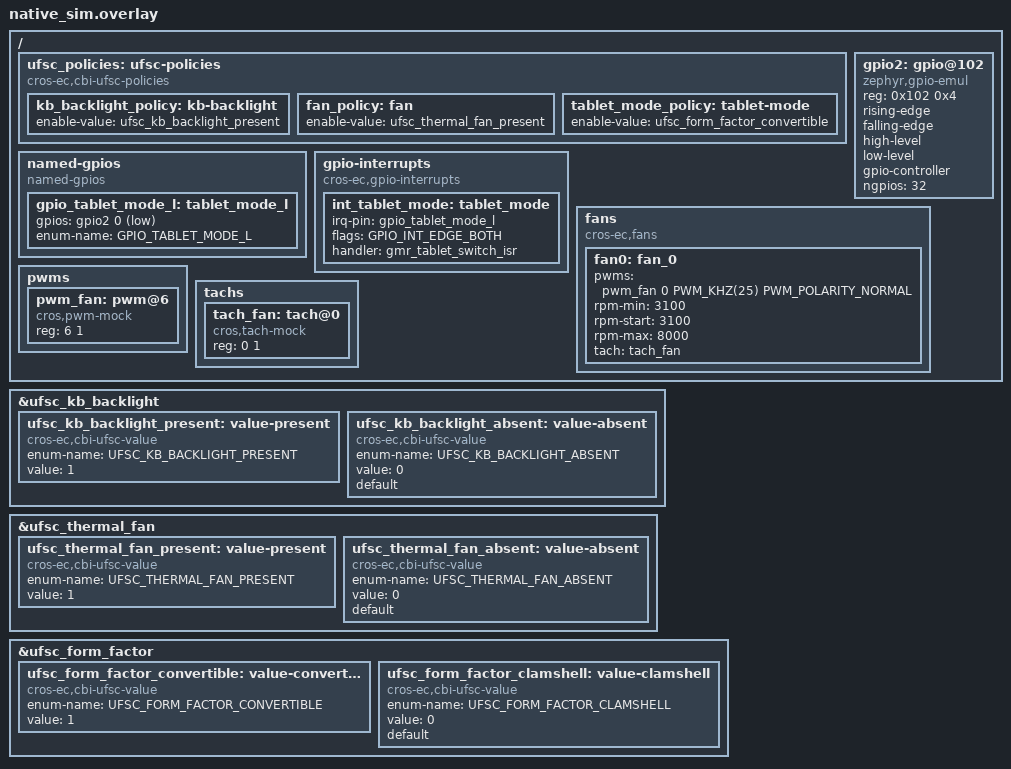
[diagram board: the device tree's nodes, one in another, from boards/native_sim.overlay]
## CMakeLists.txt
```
# Copyright 2026 The ChromiumOS Authors
# Use of this source code is governed by a BSD-style license that can be
# found in the LICENSE file.

zephyr_include_directories(include)

target_sources(app PRIVATE
	src/mock_cbi.c
	src/ufsc_kb_backlight.c
	src/ufsc_thermal_fan.c
	src/ufsc_tablet_mode.c
)
```

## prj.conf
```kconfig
# Copyright 2026 The ChromiumOS Authors
# Use of this source code is governed by a BSD-style license that can be
# found in the LICENSE file.

CONFIG_PLATFORM_EC_CBI_FLASH=y
CONFIG_PLATFORM_EC_PWM_KBLIGHT=y
CONFIG_PLATFORM_EC_FLASH_SIZE_BYTES=0x80000
CONFIG_PLATFORM_EC_GMR_TABLET_MODE=y
CONFIG_PLATFORM_EC_TABLET_MODE=y
CONFIG_PLATFORM_EC_TABLET_MODE_SWITCH=y
```

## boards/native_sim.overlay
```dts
/* Copyright 2026 The ChromiumOS Authors
 * Use of this source code is governed by a BSD-style license that can be
 * found in the LICENSE file.
 */

#include <cros/cbi_ufsc_std_schema.dtsi>

/ {
	ufsc_policies: ufsc-policies {
		compatible = "cros-ec,cbi-ufsc-policies";

		kb_backlight_policy: kb-backlight {
			enable-value = <&ufsc_kb_backlight_present>;
		};

		fan_policy: fan {
			enable-value = <&ufsc_thermal_fan_present>;
		};

		tablet_mode_policy: tablet-mode {
			enable-value = <&ufsc_form_factor_convertible>;
		};
	};

	gpio2: gpio@102 {
		status = "okay";
		compatible = "zephyr,gpio-emul";
		reg = <0x102 0x4>;
		rising-edge;
		falling-edge;
		high-level;
		low-level;
		gpio-controller;
		#gpio-cells = <2>;
		ngpios = <32>;
	};

	named-gpios {
		compatible = "named-gpios";

		gpio_tablet_mode_l: tablet_mode_l {
			gpios = <&gpio2 0 (GPIO_INPUT | GPIO_ACTIVE_LOW)>;
			enum-name = "GPIO_TABLET_MODE_L";
		};
	};

	gpio-interrupts {
		compatible = "cros-ec,gpio-interrupts";

		int_tablet_mode: tablet_mode {
			irq-pin = <&gpio_tablet_mode_l>;
			flags = <GPIO_INT_EDGE_BOTH>;
			handler = "gmr_tablet_switch_isr";
		};
	};

	fans {
		compatible = "cros-ec,fans";

		fan0: fan_0 {
			pwms = <&pwm_fan 0 PWM_KHZ(25) PWM_POLARITY_NORMAL>;
			rpm-min = <3100>;
			rpm-start = <3100>;
			rpm-max = <8000>;
			tach = <&tach_fan>;
		};
	};

	pwms {
		pwm_fan: pwm@6 {
			compatible = "cros,pwm-mock";
			reg = <6 1>;
			#pwm-cells = <3>;
			status = "okay";
		};
	};

	tachs {
		#address-cells = <1>;
		#size-cells = <1>;

		tach_fan: tach@0 {
			compatible = "cros,tach-mock";
			reg = <0 1>;
			#tach-cells = <3>;
			status = "okay";
		};
	};
};

&ufsc_kb_backlight {
	status = "okay";
	ufsc_kb_backlight_present: value-present {
		compatible = "cros-ec,cbi-ufsc-value";
		status = "okay";
		enum-name = "UFSC_KB_BACKLIGHT_PRESENT";
		value = <1>;
	};
	ufsc_kb_backlight_absent: value-absent {
		compatible = "cros-ec,cbi-ufsc-value";
		status = "okay";
		enum-name = "UFSC_KB_BACKLIGHT_ABSENT";
		value = <0>;
		default;
	};
};

&ufsc_thermal_fan {
	status = "okay";
	ufsc_thermal_fan_present: value-present {
		compatible = "cros-ec,cbi-ufsc-value";
		status = "okay";
		enum-name = "UFSC_THERMAL_FAN_PRESENT";
		value = <1>;
	};
	ufsc_thermal_fan_absent: value-absent {
		compatible = "cros-ec,cbi-ufsc-value";
		status = "okay";
		enum-name = "UFSC_THERMAL_FAN_ABSENT";
		value = <0>;
		default;
	};
};

&ufsc_form_factor {
	status = "okay";
	ufsc_form_factor_convertible: value-convertible {
		compatible = "cros-ec,cbi-ufsc-value";
		status = "okay";
		enum-name = "UFSC_FORM_FACTOR_CONVERTIBLE";
		value = <1>;
	};
	ufsc_form_factor_clamshell: value-clamshell {
		compatible = "cros-ec,cbi-ufsc-value";
		status = "okay";
		enum-name = "UFSC_FORM_FACTOR_CLAMSHELL";
		value = <0>;
		default;
	};
};
```

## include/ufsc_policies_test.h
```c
/* Copyright 2026 The ChromiumOS Authors
 * Use of this source code is governed by a BSD-style license that can be
 * found in the LICENSE file.
 */

#ifndef PLATFORM_EC_ZEPHYR_TEST_DRIVERS_UFSC_POLICIES_INCLUDE_UFSC_POLICIES_TEST_H_
#define PLATFORM_EC_ZEPHYR_TEST_DRIVERS_UFSC_POLICIES_INCLUDE_UFSC_POLICIES_TEST_H_

#include "cros_cbi.h"

#include <zephyr/fff.h>

DECLARE_FAKE_VALUE_FUNC(bool, cros_cbi_ufsc_check_match,
			enum cbi_ufsc_value_id);

#endif /* PLATFORM_EC_ZEPHYR_TEST_DRIVERS_UFSC_POLICIES_INCLUDE_UFSC_POLICIES_TEST_H_ \
	*/
```

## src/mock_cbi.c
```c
/* Copyright 2026 The ChromiumOS Authors
 * Use of this source code is governed by a BSD-style license that can be
 * found in the LICENSE file.
 */

#include "ufsc_policies_test.h"

DEFINE_FAKE_VALUE_FUNC(bool, cros_cbi_ufsc_check_match, enum cbi_ufsc_value_id);
```

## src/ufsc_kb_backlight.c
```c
/* Copyright 2026 The ChromiumOS Authors
 * Use of this source code is governed by a BSD-style license that can be
 * found in the LICENSE file.
 */

#include "cros_cbi.h"
#include "ec_commands.h"
#include "hooks.h"
#include "host_command.h"
#include "keyboard_backlight.h"
#include "system.h"
#include "ufsc_policies_test.h"

#include <zephyr/fff.h>
#include <zephyr/ztest.h>

#define VALUE_NODE_PRESENT DT_NODELABEL(ufsc_kb_backlight_present)

static bool mock_ufsc_kb_backlight_present;

static bool mock_cbi_ufsc_check_match(enum cbi_ufsc_value_id value_id)
{
	if (value_id == CBI_UFSC_VALUE_ID(VALUE_NODE_PRESENT)) {
		return mock_ufsc_kb_backlight_present;
	}
	/* Default to false for any other UFSC checks in the system */
	return false;
}

static void ufsc_kb_backlight_before(void *data)
{
	ARG_UNUSED(data);

	/* Replace the real function with our custom fake. */
	cros_cbi_ufsc_check_match_fake.custom_fake = mock_cbi_ufsc_check_match;

	/*
	 * Reset the backlight module to its default "on" state. The 'enabled'
	 * variable inside keyboard_backlight.c is static and its state
	 * persists between test runs.
	 */
	kblight_enable(1);
}

ZTEST_SUITE(ufsc_kb_backlight, NULL, NULL, ufsc_kb_backlight_before, NULL,
	    NULL);

ZTEST(ufsc_kb_backlight, test_kblight_present)
{
	/* Emulate the KB backlight check matched. */
	mock_ufsc_kb_backlight_present = true;

	hook_notify(HOOK_INIT);
	zassert_true(kblight_get_current_enable(), "kblight should be enabled");
	zassert_true((get_feature_flags0() &
		      EC_FEATURE_MASK_0(EC_FEATURE_PWM_KEYB)),
		     "EC_FEATURE_PWM_KEYB should be present in flags");
}

ZTEST(ufsc_kb_backlight, test_kblight_absent)
{
	/* Emulate the KB backlight check mismatched. */
	mock_ufsc_kb_backlight_present = false;

	hook_notify(HOOK_INIT);
	zassert_false(kblight_get_current_enable(),
		      "kblight should be disabled");
	zassert_false((get_feature_flags0() &
		       EC_FEATURE_MASK_0(EC_FEATURE_PWM_KEYB)),
		      "EC_FEATURE_PWM_KEYB should be absent from flags");
}
```

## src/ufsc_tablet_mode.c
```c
/* Copyright 2026 The ChromiumOS Authors
 * Use of this source code is governed by a BSD-style license that can be
 * found in the LICENSE file.
 */

#include "cros_cbi.h"
#include "hooks.h"
#include "tablet_mode.h"
#include "ufsc_policies_test.h"

#include <zephyr/fff.h>
#include <zephyr/ztest.h>

#define VALUE_NODE_CONVERTIBLE DT_NODELABEL(ufsc_form_factor_convertible)

static bool mock_ufsc_form_factor_convertible;

static bool mock_cbi_ufsc_check_match_tablet(enum cbi_ufsc_value_id value_id)
{
	if (value_id == CBI_UFSC_VALUE_ID(VALUE_NODE_CONVERTIBLE)) {
		return mock_ufsc_form_factor_convertible;
	}
	return false;
}

static void ufsc_tablet_mode_before(void *data)
{
	ARG_UNUSED(data);

	cros_cbi_ufsc_check_match_fake.custom_fake =
		mock_cbi_ufsc_check_match_tablet;

	tablet_reset();
}

ZTEST_SUITE(ufsc_tablet_mode, NULL, NULL, ufsc_tablet_mode_before, NULL, NULL);

ZTEST(ufsc_tablet_mode, test_tablet_mode_convertible)
{
	mock_ufsc_form_factor_convertible = true;

	hook_notify(HOOK_INIT);
	tablet_set_mode(1, TABLET_TRIGGER_LID);
	zassert_equal(tablet_get_mode(), 1,
		      "tablet mode should be enabled for convertible");
}

ZTEST(ufsc_tablet_mode, test_tablet_mode_clamshell)
{
	mock_ufsc_form_factor_convertible = false;

	hook_notify(HOOK_INIT);
	tablet_set_mode(1, TABLET_TRIGGER_LID);
	zassert_equal(tablet_get_mode(), 0,
		      "tablet mode should remain disabled for clamshell");
}
```

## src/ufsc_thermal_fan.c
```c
/* Copyright 2026 The ChromiumOS Authors
 * Use of this source code is governed by a BSD-style license that can be
 * found in the LICENSE file.
 */

#include "cros_cbi.h"
#include "fan.h"
#include "hooks.h"
#include "ufsc_policies_test.h"

#include <zephyr/fff.h>
#include <zephyr/ztest.h>

#define VALUE_NODE_PRESENT DT_NODELABEL(ufsc_thermal_fan_present)

static bool mock_ufsc_thermal_fan_present;

static bool mock_cbi_ufsc_check_match_fan(enum cbi_ufsc_value_id value_id)
{
	if (value_id == CBI_UFSC_VALUE_ID(VALUE_NODE_PRESENT)) {
		return mock_ufsc_thermal_fan_present;
	}
	return false;
}

static void ufsc_thermal_fan_before(void *data)
{
	ARG_UNUSED(data);

	cros_cbi_ufsc_check_match_fake.custom_fake =
		mock_cbi_ufsc_check_match_fan;

	/* Reset fan count to default CONFIG_FANS */
	fan_set_count(CONFIG_FANS);
}

ZTEST_SUITE(ufsc_thermal_fan, NULL, NULL, ufsc_thermal_fan_before, NULL, NULL);

ZTEST(ufsc_thermal_fan, test_fan_present)
{
	mock_ufsc_thermal_fan_present = true;

	hook_notify(HOOK_INIT);
	zassert_equal(fan_get_count(), 1, "fan count should remain 1");
}

ZTEST(ufsc_thermal_fan, test_fan_absent)
{
	mock_ufsc_thermal_fan_present = false;

	hook_notify(HOOK_INIT);
	zassert_equal(fan_get_count(), 0, "fan count should be set to 0");
}
```
